# A31L12x register map
Vendor: VENDOR ABOV Semiconductor Co., Ltd.; Series: A31L12x; File version: 1.0
CPU: CM0+ r0p1, little endian, no MPU, no FPU, VTOR, 2 interrupt priority bits
Registers are 32-bit, read-write, reset 0x0 unless marked. A register's access mark holds for its fields unless they carry their own. Offsets are from the block's base; [hi:lo] are bit positions; {n}, {i} and the like mark numbered series.

## I2Cn
Base 0x58000000
Same registers: I2C0 0x40004800, I2C1 0x40004900
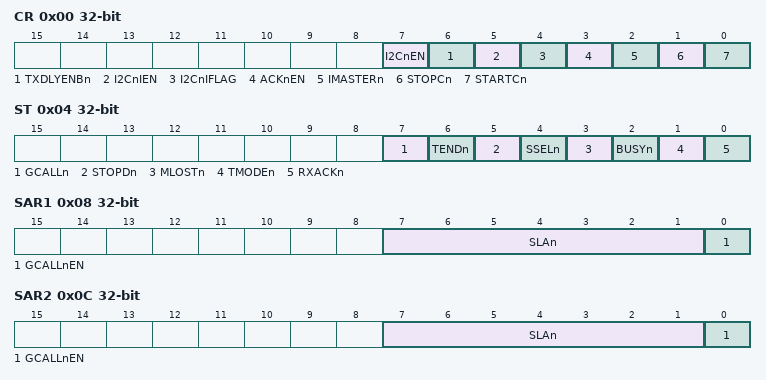
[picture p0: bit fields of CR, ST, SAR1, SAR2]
0x00 CR — I2Cn Control Register
  [7] I2CnEN — Activate I2Cn Block by supplying
  [6] TXDLYENBn — I2CnSDHR Register Control
  [5] I2CnIEN — I2Cn Interrupt Enable
  [4] I2CnIFLAG — I2Cn Interrupt Flag
  [3] ACKnEN — Controls ACK signal generation at ninth SCL period
  [2] IMASTERn ro — Represent Operation Mode of I2Cn
  [1] STOPCn — STOP Condition Generation When I2Cn is master
  [0] STARTCn — START Condition Generation When I2Cn is master
0x04 ST — I2Cn Status Register
  [7] GCALLn — This bit has different meaning depending on whether I2C is master or slave
  [6] TENDn — This bit is set when 1-byte of data is transferred completely
  [5] STOPDn — This bit is set when a STOP condition is detected
  [4] SSELn — This bit is set when I2C is addressed by other master
  [3] MLOSTn — This bit represents the result of bus arbitration in master mode
  [2] BUSYn — This bit reflects bus status
  [1] TMODEn ro — This bit is used to indicate whether I2C is transmitter or receiver
  [0] RXACKn — This bit shows the state of ACK signal
0x08 SAR1 — I2Cn Slave Address Register 1
  [7:1] SLAn — These bits configure the slave address 0 in slave mode
  [0] GCALLnEN — This bit decides whether I2Cn allows general call address 0 or not in I2Cn slave mode
0x0C SAR2 — I2Cn Slave Address Register 2
  [7:1] SLAn — These bits configure the slave address 1 in slave mode
  [0] GCALLnEN — This bit decides whether I2Cn allows general call address 1 or not in I2Cn slave mode
0x10 DR — I2Cn Data Register
  [7:0] DATA — The I2CnDR Transmit buffer and Receive buffer share the same I/O address with this DATA register
0x14 SDHR reset 0x1 — I2Cn SDA Hold Time Register
  [11:0] HLDT — This register is used to control SDA output timing from the falling edge of SCL
0x18 SCLR reset 0x3F — I2Cn SCL Low Period Register
  [11:0] SCLL — This register defines the low period of SCL in master mode
0x1C SCHR reset 0x3F — I2Cn SCL High Period Register
  [11:0] SCLH — This register defines the high period of SCL in master mode

## LCD — LCD Driver
Base 0x40005000
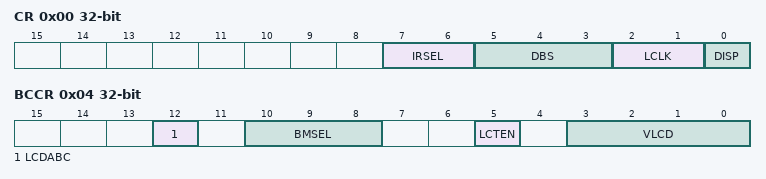
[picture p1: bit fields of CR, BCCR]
0x00 CR — LCD Driver Control Register
  [7:6] IRSEL — Internal LCD Bias Dividing Resistor Selection
    0=RLCD3 (105/105/80[kohm] @(1/2)/(1/3)/(1/4) bias); 1=RLCD1 (10/10/10[kohm] @(1/2)/(1/3)/(1/4) bias); 2=RLCD2 (66/66/50[kohm] @(1/2)/(1/3)/(1/4) bias); 3=RLCD4 (320/320/240[kohm] @(1/2)/(1/3)/(1/4) bias)
  [5:3] DBS — LCD Duty and Bias Selection
    0=8D4B (1/8 duty, 1/4 bias); 1=6D4B (1/6 duty, 1/4 bias); 2=5D3B (1/5 duty, 1/3 bias); 3=4D3B (1/4 duty, 1/3 bias); 4=3D3B (1/3 duty, 1/3 bias); 5=3D2B (1/3 duty, 1/2 bias)
  [2:1] LCLK — LCD Clock Selection (When fLCD = 32.768kHz)
    0=128Hz (32.768kHz(fLCD) / 256); 1=256Hz (32.768kHz(fLCD) / 128); 2=512Hz (32.768kHz(fLCD) / 64); 3=1024Hz (32.768kHz(fLCD) / 32)
  [0] DISP — LCD Display Control
    0=Off (Display off); 1=On (Normal display on)
0x04 BCCR — LCD Automatic Bias and Contrast Control Register
  [12] LCDABC — LCD Automatic Bias Control
    0=Off (LCD automatic bias is off); 1=On (LCD automatic bias is on)
  [10:8] BMSEL — 'Bias Mode A' Time Selection
    {v}=BMA{v+1}Clk ('Bias Mode A' for {v+1}-clock of fLCD) (v=0..7)
  [5] LCTEN — LCD Driver Contrast Control
    0=Disable LCD driver contrast; 1=Enable LCD driver contrast
  [3:0] VLCD — VLC0 Voltage Control when the contrast is enabled
    0=Step0 (VDD x 32/47 Step); 1=Step1 (VDD x 32/46 Step); 2=Step2 (VDD x 32/45 Step); 3=Step3 (VDD x 32/44 Step); 4=Step4 (VDD x 32/43 Step); 5=Step5 (VDD x 32/42 Step); 6=Step6 (VDD x 32/41 Step); 7=Step7 (VDD x 32/40 Step); 8=Step8 (VDD x 32/39 Step); 9=Step9 (VDD x 32/38 Step); 10=Step10 (VDD x 32/37 Step); 11=Step11 (VDD x 32/36 Step); 12=Step12 (VDD x 32/35 Step); 13=Step13 (VDD x 32/34 Step); 14=Step14 (VDD x 32/33 Step); 15=Step15 (VDD x 32/32 Step)
{0x10+i} DR{i} 8-bit reset not defined (i=0..32) — LCD Display Data Register {i}

## Notices in the file
Copyright (C) 2012 ARM Limited. All rights reserved.
Purpose: System Viewer Description (SVD) Example (Schema Version 1.1)
This is a description of a none-existent and incomplete device
for demonstration purposes only.
Redistribution and use in source and binary forms, with or without
modification, are permitted provided that the following conditions are met:
- Redistributions of source code must retain the above copyright
notice, this list of conditions and the following disclaimer.
- Redistributions in binary form must reproduce the above copyright
notice, this list of conditions and the following disclaimer in the
documentation and/or other materials provided with the distribution.
- Neither the name of ARM nor the names of its contributors may be used
to endorse or promote products derived from this software without
specific prior written permission.
THIS SOFTWARE IS PROVIDED BY THE COPYRIGHT HOLDERS AND CONTRIBUTORS "AS IS"
AND ANY EXPRESS OR IMPLIED WARRANTIES, INCLUDING, BUT NOT LIMITED TO, THE
IMPLIED WARRANTIES OF MERCHANTABILITY AND FITNESS FOR A PARTICULAR PURPOSE
ARE DISCLAIMED. IN NO EVENT SHALL COPYRIGHT HOLDERS AND CONTRIBUTORS BE
LIABLE FOR ANY DIRECT, INDIRECT, INCIDENTAL, SPECIAL, EXEMPLARY, OR
CONSEQUENTIAL DAMAGES (INCLUDING, BUT NOT LIMITED TO, PROCUREMENT OF
SUBSTITUTE GOODS OR SERVICES; LOSS OF USE, DATA, OR PROFITS; OR BUSINESS
INTERRUPTION) HOWEVER CAUSED AND ON ANY THEORY OF LIABILITY, WHETHER IN
CONTRACT, STRICT LIABILITY, OR TORT (INCLUDING NEGLIGENCE OR OTHERWISE)
ARISING IN ANY WAY OUT OF THE USE OF THIS SOFTWARE, EVEN IF ADVISED OF THE
POSSIBILITY OF SUCH DAMAGE.
